AUTOSAR XML (schema 00046)
package /COM/VECTOR/CFG/WORKFLOW/SYSDESC/SYNC
  system SYSTEM: category=ECU_EXTRACT
    system mapping MAPPINGS: data-mappings={sender-receiver-to-signal-group-mapping={data-element=COMPOSITIONTYPE.R_DI_Odo_Pr5_ST3.DI_Odo_Pr5_ST3, signal-group=DI_Odo_Pr5_ST3_e68xmtlkywxgxsdwekdjjhw3t, type-mapping=sender-rec-record-type-mapping=sender-rec-record-element-mapping{application-record-element=Odo_ST3, system-signal=Odo_ST3}}, sender-receiver-to-signal-mapping={data-element=COMPOSITIONTYPE.R_DidA_ExtTest_Pres_ST3.DidA_ExtTest_Pres_ST3, system-signal=DidA_ExtTest_Pres_ST3}, sender-receiver-to-signal-group-mapping={data-element=COMPOSITIONTYPE.R_Ign_Stat_Pr5_ST3.Ign_Stat_Pr5_ST3, signal-group=Ign_Stat_Pr5_ST3_csgs1dv6drms80o1i9p49677w, type-mapping=sender-rec-record-type-mapping=record-element-mappings=[{application-record-element=KG_StartSw_Psd_ST3, system-signal=KG_StartSw_Psd_ST3}, {application-record-element=CRC_Ign_Stat_Pr5_ST3, system-signal=CRC_Ign_Stat_Pr5_ST3}, {application-record-element=Veh_Op_Mode_ST3, system-signal=Veh_Op_Mode_ST3}, {application-record-element=ISw_Stat_ST3, system-signal=ISw_Stat_ST3}, {application-record-element=SQC_Ign_Stat_Pr5_ST3, system-signal=SQC_Ign_Stat_Pr5_ST3}]}, sender-receiver-to-signal-mapping={data-element=COMPOSITIONTYPE.R_PN14_ProdMd_Stat_ST3.PN14_ProdMd_Stat_ST3, system-signal=PN14_ProdMd_Stat_ST3}, sender-receiver-to-signal-mapping={data-element=COMPOSITIONTYPE.R_PN14_SupBat_Volt_ST3.PN14_SupBat_Volt_ST3, system-signal=PN14_SupBat_Volt_ST3}, sender-receiver-to-signal-mapping={data-element=COMPOSITIONTYPE.R_PN14_TransMd_Stat_ST3.PN14_TransMd_Stat_ST3, system-signal=PN14_TransMd_Stat_ST3}, sender-receiver-to-signal-group-mapping={data-element=COMPOSITIONTYPE.R_VSS_TP_Auth_ST3.VSS_TP_Auth_ST3, signal-group=VSS_TP_Auth_ST3_6j4id7sghlvlbroli4wjozjik, type-mapping=sender-rec-array-type-mapping=array-element-mappings=[{indexed-array-element={application-array-element=ARRAY_ELEMENT, index=0}, system-signal=VSS_TP_Auth_0_ST3}, {indexed-array-element={application-array-element=ARRAY_ELEMENT, index=1}, system-signal=VSS_TP_Auth_1_ST3}, {indexed-array-element={application-array-element=ARRAY_ELEMENT, index=2}, system-signal=VSS_TP_Auth_2_ST3}, {indexed-array-element={application-array-element=ARRAY_ELEMENT, index=3}, system-signal=VSS_TP_Auth_3_ST3}, {indexed-array-element={application-array-element=ARRAY_ELEMENT, index=4}, system-signal=VSS_TP_Auth_4_ST3}, {indexed-array-element={application-array-element=ARRAY_ELEMENT, index=5}, system-signal=VSS_TP_Auth_5_ST3}, {indexed-array-element={application-array-element=ARRAY_ELEMENT, index=6}, system-signal=VSS_TP_Auth_6_ST3}, {indexed-array-element={application-array-element=ARRAY_ELEMENT, index=7}, system-signal=VSS_TP_Auth_7_ST3}]}, sender-receiver-to-signal-group-mapping={data-element=COMPOSITIONTYPE.R_VSS_TP_RealTmOffset_ST3.VSS_TP_RealTmOffset_ST3, signal-group=VSS_TP_RealTmOffset_ST3_1t7vc44gftc0wv35k5kgc2in9, type-mapping=sender-rec-array-type-mapping=array-element-mappings=[{indexed-array-element={application-array-element=ARRAY_ELEMENT, index=0}, system-signal=VSS_TP_RealTmOffset_0_ST3}, {indexed-array-element={application-array-element=ARRAY_ELEMENT, index=1}, system-signal=VSS_TP_RealTmOffset_1_ST3}, {indexed-array-element={application-array-element=ARRAY_ELEMENT, index=2}, system-signal=VSS_TP_RealTmOffset_2_ST3}, {indexed-array-element={application-array-element=ARRAY_ELEMENT, index=3}, system-signal=VSS_TP_RealTmOffset_3_ST3}, {indexed-array-element={application-array-element=ARRAY_ELEMENT, index=4}, system-signal=VSS_TP_RealTmOffset_4_ST3}, {indexed-array-element={application-array-element=ARRAY_ELEMENT, index=5}, system-signal=VSS_TP_RealTmOffset_5_ST3}, {indexed-array-element={application-array-element=ARRAY_ELEMENT, index=6}, system-signal=VSS_TP_RealTmOffset_6_ST3}, {indexed-array-element={application-array-element=ARRAY_ELEMENT, index=7}, system-signal=VSS_TP_RealTmOffset_7_ST3}]}, sender-receiver-to-signal-group-mapping={data-element=COMPOSITIONTYPE.R_VSS_TP_SharedSecret_ST3.VSS_TP_SharedSecret_ST3, signal-group=VSS_TP_SharedSecret_ST3_8pj4t8t4rm3tw3pk5hj7vonti, type-mapping=sender-rec-array-type-mapping=array-element-mappings=[{indexed-array-element={application-array-element=ARRAY_ELEMENT, index=0}, system-signal=VSS_TP_SharedSecret_0_ST3}, {indexed-array-element={application-array-element=ARRAY_ELEMENT, index=1}, system-signal=VSS_TP_SharedSecret_1_ST3}, {indexed-array-element={application-array-element=ARRAY_ELEMENT, index=2}, system-signal=VSS_TP_SharedSecret_2_ST3}, {indexed-array-element={application-array-element=ARRAY_ELEMENT, index=3}, system-signal=VSS_TP_SharedSecret_3_ST3}, {indexed-array-element={application-array-element=ARRAY_ELEMENT, index=4}, system-signal=VSS_TP_SharedSecret_4_ST3}, {indexed-array-element={application-array-element=ARRAY_ELEMENT, index=5}, system-signal=VSS_TP_SharedSecret_5_ST3}, {indexed-array-element={application-array-element=ARRAY_ELEMENT, index=6}, system-signal=VSS_TP_SharedSecret_6_ST3}, {indexed-array-element={application-array-element=ARRAY_ELEMENT, index=7}, system-signal=VSS_TP_SharedSecret_7_ST3}]}, sender-receiver-to-signal-group-mapping={data-element=COMPOSITIONTYPE.R_VSS_TP_VIN_ST3.VSS_TP_VIN_ST3, signal-group=VSS_TP_VIN_ST3_bz1xsv84cxzl09j028gn39p69, type-mapping=sender-rec-array-type-mapping=array-element-mappings=[{indexed-array-element={application-array-element=ARRAY_ELEMENT, index=0}, system-signal=VSS_TP_VIN_0_ST3}, {indexed-array-element={application-array-element=ARRAY_ELEMENT, index=1}, system-signal=VSS_TP_VIN_1_ST3}, {indexed-array-element={application-array-element=ARRAY_ELEMENT, index=2}, system-signal=VSS_TP_VIN_2_ST3}, {indexed-array-element={application-array-element=ARRAY_ELEMENT, index=3}, system-signal=VSS_TP_VIN_3_ST3}, {indexed-array-element={application-array-element=ARRAY_ELEMENT, index=4}, system-signal=VSS_TP_VIN_4_ST3}, {indexed-array-element={application-array-element=ARRAY_ELEMENT, index=5}, system-signal=VSS_TP_VIN_5_ST3}, {indexed-array-element={application-array-element=ARRAY_ELEMENT, index=6}, system-signal=VSS_TP_VIN_6_ST3}, {indexed-array-element={application-array-element=ARRAY_ELEMENT, index=7}, system-signal=VSS_TP_VIN_7_ST3}]}, sender-receiver-to-signal-mapping={data-element=COMPOSITIONTYPE.P_Awake_Diag_Actv_ECU4.Awake_Diag_Actv_ECU4, system-signal=Awake_Diag_Actv_ECU4}, sender-receiver-to-signal-mapping={data-element=COMPOSITIONTYPE.P_Awake_Ignition_On_C04.Awake_Ignition_On_C04, system-signal=Awake_Ignition_On_C04}, sender-receiver-to-signal-mapping={data-element=COMPOSITIONTYPE.P_Awake_NwStart_Cluster_ECU4.Awake_NwStart_Cluster_ECU4, system-signal=Awake_NwStart_Cluster_ECU4}, sender-receiver-to-signal-group-mapping={data-element=COMPOSITIONTYPE.P_COM_C04_SGR01_P05.COM_C04_SGR01_P05, signal-group=COM_C04_SGR01_P05_5t2743h81pbparal6h2spw309, type-mapping=sender-rec-record-type-mapping=record-element-mappings=[{application-record-element=COM_C04_Sig004, system-signal=COM_C04_Sig004}, {application-record-element=CRC_COM_C04_SGR01_P05, system-signal=CRC_COM_C04_SGR01_P05}, {application-record-element=SQC_COM_C04_SGR01_P05, system-signal=SQC_COM_C04_SGR01_P05}]}, client-server-to-signal-mapping={call-signal=COM_C04_Sig002_Call, client-server-operation=COMPOSITIONTYPE.P_COM_C04_Sig002.CS_Operation_C04_Sig002, return-signal=COM_C04_Sig002}, sender-receiver-to-signal-mapping={data-element=COMPOSITIONTYPE.P_COM_C04_Sig003.COM_C04_Sig003, system-signal=COM_C04_Sig003}, sender-receiver-to-signal-mapping={data-element=COMPOSITIONTYPE.P_COM_C04_Sig005.COM_C04_Sig005, system-signal=COM_C04_Sig005}, sender-receiver-to-signal-mapping={data-element=COMPOSITIONTYPE.P_COM_C04_Sig006.COM_C04_Sig006, system-signal=COM_C04_Sig006}, sender-receiver-to-signal-mapping={data-element=COMPOSITIONTYPE.P_COM_C04_Sig007.COM_C04_Sig007, system-signal=COM_C04_Sig007}, sender-receiver-to-signal-mapping={data-element=COMPOSITIONTYPE.P_COM_C04_Sig008.COM_C04_Sig008, system-signal=COM_C04_Sig008}, sender-receiver-to-signal-mapping={data-element=COMPOSITIONTYPE.P_COM_C04_Sig01_PN08.COM_C04_Sig01_PN08, system-signal=COM_C04_Sig01_PN08}, sender-receiver-to-signal-mapping={data-element=COMPOSITIONTYPE.P_COM_C04_Sig01_PN17.COM_C04_Sig01_PN17, system-signal=COM_C04_Sig01_PN17}, sender-receiver-to-signal-mapping={data-element=COMPOSITIONTYPE.P_COM_C04_Sig01_PN44.COM_C04_Sig01_PN44, system-signal=COM_C04_Sig01_PN44}, sender-receiver-to-signal-mapping={data-element=COMPOSITIONTYPE.P_COM_C04_Sig01_PN53.COM_C04_Sig01_PN53, system-signal=COM_C04_Sig01_PN53}, sender-receiver-to-signal-mapping={data-element=COMPOSITIONTYPE.P_COM_C04_Sig01_PN62.COM_C04_Sig01_PN62, system-signal=COM_C04_Sig01_PN62}, sender-receiver-to-signal-mapping={data-element=COMPOSITIONTYPE.P_COM_C04_Sig110.COM_C04_Sig110, system-signal=COM_C04_Sig110}, sender-receiver-to-signal-mapping={data-element=COMPOSITIONTYPE.P_COM_C04_Sig111.COM_C04_Sig111, system-signal=COM_C04_Sig111}, sender-receiver-to-signal-mapping={data-element=COMPOSITIONTYPE.P_COM_C04_Sig112.COM_C04_Sig112, system-signal=COM_C04_Sig112}, sender-receiver-to-signal-mapping={data-element=COMPOSITIONTYPE.P_COM_C04_Sig113.COM_C04_Sig113, system-signal=COM_C04_Sig113}, sender-receiver-to-signal-mapping={data-element=COMPOSITIONTYPE.P_COM_C04_Sig114.COM_C04_Sig114, system-signal=COM_C04_Sig114}, sender-receiver-to-signal-mapping={data-element=COMPOSITIONTYPE.P_COM_C04_Sig115.COM_C04_Sig115, system-signal=COM_C04_Sig115}, sender-receiver-to-signal-mapping={data-element=COMPOSITIONTYPE.P_COM_C04_Sig116.COM_C04_Sig116, system-signal=COM_C04_Sig116}, sender-receiver-to-signal-mapping={data-element=COMPOSITIONTYPE.P_COM_C04_Sig117.COM_C04_Sig117, system-signal=COM_C04_Sig117}, sender-receiver-to-signal-mapping={data-element=COMPOSITIONTYPE.P_COM_C04_Sig118.COM_C04_Sig118, system-signal=COM_C04_Sig118}, sender-receiver-to-signal-mapping={data-element=COMPOSITIONTYPE.P_COM_C04_Sig119.COM_C04_Sig119, system-signal=COM_C04_Sig119}, sender-receiver-to-signal-mapping={data-element=COMPOSITIONTYPE.P_COM_C04_Sig120.COM_C04_Sig120, system-signal=COM_C04_Sig120}, sender-receiver-to-signal-mapping={data-element=COMPOSITIONTYPE.P_COM_C04_Sig121.COM_C04_Sig121, system-signal=COM_C04_Sig121}, sender-receiver-to-signal-mapping={data-element=COMPOSITIONTYPE.P_COM_C04_Sig1Cyc_1.COM_C04_Sig1Cyc_1, system-signal=COM_C04_Sig1Cyc_1}, sender-receiver-to-signal-mapping={data-element=COMPOSITIONTYPE.P_COM_C04_Sig221.COM_C04_Sig221, system-signal=COM_C04_Sig221}, sender-receiver-to-signal-mapping={data-element=COMPOSITIONTYPE.P_COM_C04_Sig2Cyc_7.COM_C04_Sig2Cyc_7, system-signal=COM_C04_Sig2Cyc_7}, sender-receiver-to-signal-mapping={data-element=COMPOSITIONTYPE.P_COM_C04_Sig3Cyc_9.COM_C04_Sig3Cyc_9, system-signal=COM_C04_Sig3Cyc_9}, sender-receiver-to-signal-mapping={data-element=COMPOSITIONTYPE.P_COM_C04_Sig4Cyc_24.COM_C04_Sig4Cyc_24, system-signal=COM_C04_Sig4Cyc_24}, sender-receiver-to-signal-mapping={data-element=COMPOSITIONTYPE.P_ECU_ID_C04.ECU_ID_C04, system-signal=ECU_ID_C04}, sender-receiver-to-signal-mapping={data-element=COMPOSITIONTYPE.P_NwId_C04_CAN1.NwId_C04_CAN1, system-signal=NwId_C04_CAN1}, sender-receiver-to-signal-mapping={data-element=COMPOSITIONTYPE.P_NwId_C04_CANFD1.NwId_C04_CANFD1, system-signal=NwId_C04_CANFD1}, sender-receiver-to-signal-mapping={data-element=COMPOSITIONTYPE.P_NwId_C04_ETH_ECU4.NwId_C04_ETH_ECU4, system-signal=NwId_C04_ETH_ECU4}, sender-receiver-to-signal-group-mapping={data-element=COMPOSITIONTYPE.P_ROE.ROE_XX_ST3, signal-group=Diag_RoE_C04_SigGrp01_2ksq5hjijyze6lf3nboiafq6k, type-mapping=sender-rec-record-type-mapping=record-element-mappings=[{application-record-element=ROE_0, system-signal=Diag_RoE_C04_Sig00}, {application-record-element=ROE_4, system-signal=Diag_RoE_C04_Sig04}, {application-record-element=ROE_3, system-signal=Diag_RoE_C04_Sig03}, {application-record-element=ROE_1, system-signal=Diag_RoE_C04_Sig01}, {application-record-element=ROE_2, system-signal=Diag_RoE_C04_Sig02}, {application-record-element=ROE_5, system-signal=Diag_RoE_C04_Sig05}, {application-record-element=ROE_6, system-signal=Diag_RoE_C04_Sig06}, {application-record-element=ROE_7, system-signal=Diag_RoE_C04_Sig07}]}, sender-receiver-to-signal-group-mapping={data-element=COMPOSITIONTYPE.P_VSS_TP_SecTickCount_ST3.VSS_TP_SecTickCount_ST3, signal-group=VSS_TP_SecTickCount_Lvl2_ST3_9eubq13iosat764o0lqh5xb6r, type-mapping=sender-rec-array-type-mapping=array-element-mappings=[{indexed-array-element={application-array-element=ARRAY_ELEMENT, index=0}, system-signal=VSS_TP_SecTickCount_Lvl2_0_ST3}, {indexed-array-element={application-array-element=ARRAY_ELEMENT, index=1}, system-signal=VSS_TP_SecTickCount_Lvl2_1_ST3}, {indexed-array-element={application-array-element=ARRAY_ELEMENT, index=2}, system-signal=VSS_TP_SecTickCount_Lvl2_2_ST3}, {indexed-array-element={application-array-element=ARRAY_ELEMENT, index=3}, system-signal=VSS_TP_SecTickCount_Lvl2_3_ST3}, {indexed-array-element={application-array-element=ARRAY_ELEMENT, index=4}, system-signal=VSS_TP_SecTickCount_Lvl2_4_ST3}, {indexed-array-element={application-array-element=ARRAY_ELEMENT, index=5}, system-signal=VSS_TP_SecTickCount_Lvl2_5_ST3}, {indexed-array-element={application-array-element=ARRAY_ELEMENT, index=6}, system-signal=VSS_TP_SecTickCount_Lvl2_6_ST3}, {indexed-array-element={application-array-element=ARRAY_ELEMENT, index=7}, system-signal=VSS_TP_SecTickCount_Lvl2_7_ST3}]}, sender-receiver-to-signal-mapping={data-element=COMPOSITIONTYPE.P_WakeupRsn_C04_ECU04.WakeupRsn_C04_ECU04, system-signal=WakeupRsn_C04_ECU04}, sender-receiver-to-signal-mapping={data-element=COMPOSITIONTYPE.R_COM_C01_Sig01_PN08.COM_C01_Sig01_PN08, system-signal=COM_C01_Sig01_PN08}, sender-receiver-to-signal-mapping={data-element=COMPOSITIONTYPE.R_COM_C01_Sig01_PN17.COM_C01_Sig01_PN17, system-signal=COM_C01_Sig01_PN17}, sender-receiver-to-signal-mapping={data-element=COMPOSITIONTYPE.R_COM_C01_Sig01_PN44.COM_C01_Sig01_PN44, system-signal=COM_C01_Sig01_PN44}, sender-receiver-to-signal-mapping={data-element=COMPOSITIONTYPE.R_COM_C01_Sig01_PN53.COM_C01_Sig01_PN53, system-signal=COM_C01_Sig01_PN53}, sender-receiver-to-signal-mapping={data-element=COMPOSITIONTYPE.R_COM_C01_Sig01_PN62.COM_C01_Sig01_PN62, system-signal=COM_C01_Sig01_PN62}, sender-receiver-to-signal-mapping={data-element=COMPOSITIONTYPE.R_COM_C07_Sig01_PN08.COM_C07_Sig01_PN08, system-signal=COM_C07_Sig01_PN08}, sender-receiver-to-signal-mapping={data-element=COMPOSITIONTYPE.R_COM_C07_Sig01_PN44.COM_C07_Sig01_PN44, system-signal=COM_C07_Sig01_PN44}, sender-receiver-to-signal-mapping={data-element=COMPOSITIONTYPE.R_COM_C07_Sig01_PN53.COM_C07_Sig01_PN53, system-signal=COM_C07_Sig01_PN53}, sender-receiver-to-signal-mapping={data-element=COMPOSITIONTYPE.R_COM_C0X_Sig111.COM_C0X_Sig111, system-signal=COM_C0X_Sig111}, sender-receiver-to-signal-mapping={data-element=COMPOSITIONTYPE.R_COM_C0X_Sig112.COM_C0X_Sig112, system-signal=COM_C0X_Sig112}, sender-receiver-to-signal-mapping={data-element=COMPOSITIONTYPE.R_COM_C0X_Sig113.COM_C0X_Sig113, system-signal=COM_C0X_Sig113}, sender-receiver-to-signal-mapping={data-element=COMPOSITIONTYPE.R_COM_C0X_Sig114.COM_C0X_Sig114, system-signal=COM_C0X_Sig114}, sender-receiver-to-signal-mapping={data-element=COMPOSITIONTYPE.R_COM_C0X_Sig115.COM_C0X_Sig115, system-signal=COM_C0X_Sig115}, sender-receiver-to-signal-mapping={data-element=COMPOSITIONTYPE.R_COM_C0X_Sig116.COM_C0X_Sig116, system-signal=COM_C0X_Sig116}, sender-receiver-to-signal-mapping={data-element=COMPOSITIONTYPE.R_COM_C0X_Sig117.COM_C0X_Sig117, system-signal=COM_C0X_Sig117}, sender-receiver-to-signal-mapping={data-element=COMPOSITIONTYPE.R_COM_C0X_Sig118.COM_C0X_Sig118, system-signal=COM_C0X_Sig118}, sender-receiver-to-signal-mapping={data-element=COMPOSITIONTYPE.R_COM_C0X_Sig119.COM_C0X_Sig119, system-signal=COM_C0X_Sig119}, sender-receiver-to-signal-mapping={data-element=COMPOSITIONTYPE.R_COM_C0X_Sig120.COM_C0X_Sig120, system-signal=COM_C0X_Sig120}, sender-receiver-to-signal-mapping={data-element=COMPOSITIONTYPE.R_COM_C0X_Sig121.COM_C0X_Sig121, system-signal=COM_C0X_Sig121}, sender-receiver-to-signal-mapping={data-element=COMPOSITIONTYPE.R_COM_C0X_Sig221.COM_C0X_Sig221, system-signal=COM_C0X_Sig221}, sender-receiver-to-signal-mapping={data-element=COMPOSITIONTYPE.R_COM_C10_Sig01_PN08.COM_C10_Sig01_PN08, system-signal=COM_C10_Sig01_PN08}, sender-receiver-to-signal-mapping={data-element=COMPOSITIONTYPE.R_COM_C10_Sig01_PN17.COM_C10_Sig01_PN17, system-signal=COM_C10_Sig01_PN17}, sender-receiver-to-signal-mapping={data-element=COMPOSITIONTYPE.R_COM_C19_Sig002.COM_C19_Sig002, system-signal=COM_C19_Sig002}, sender-receiver-to-signal-mapping={data-element=COMPOSITIONTYPE.R_COM_C19_Sig003.COM_C19_Sig003, system-signal=COM_C19_Sig003}, sender-receiver-to-signal-mapping={data-element=COMPOSITIONTYPE.R_COM_C19_Sig004.COM_C19_Sig004, system-signal=COM_C19_Sig004}, sender-receiver-to-signal-mapping={data-element=COMPOSITIONTYPE.R_COM_C19_Sig005.COM_C19_Sig005, system-signal=COM_C19_Sig005}, sender-receiver-to-signal-mapping={data-element=COMPOSITIONTYPE.R_COM_C19_Sig006.COM_C19_Sig006, system-signal=COM_C19_Sig006}, sender-receiver-to-signal-mapping={data-element=COMPOSITIONTYPE.R_COM_C19_Sig01_PN08.COM_C19_Sig01_PN08, system-signal=COM_C19_Sig01_PN08}, sender-receiver-to-signal-mapping={data-element=COMPOSITIONTYPE.R_COM_C19_Sig01_PN44.COM_C19_Sig01_PN44, system-signal=COM_C19_Sig01_PN44}, sender-receiver-to-signal-mapping={data-element=COMPOSITIONTYPE.R_COM_SL05_Sig001.COM_SL05_Sig001, system-signal=COM_SL05_Sig001}, sender-receiver-to-signal-group-mapping={data-element=COMPOSITIONTYPE.R_PT4_PTCoor4_Pr5_ST3.PT4_PTCoor4_Pr5_ST3, signal-group=PT4_PTCoor4_Pr5_ST3_af4fxb1ykieox3itqdfzs0kpb, type-mapping=sender-rec-record-type-mapping=record-element-mappings=[{application-record-element=PT4_PTCoor_EngStartPN14_Stat_ST3, system-signal=PT4_PTCoor_EngStartPN14_Stat_ST3}, {application-record-element=Rsrv1_PT4_PTCoor_PT_Rdy_Pr5_ST3, system-signal=Rsrv1_PT4_PTCoor_PT_Rdy_Pr5_ST3}, {application-record-element=PT4_PTCoor_PT_Rdy_ST3, system-signal=PT4_PTCoor_PT_Rdy_ST3}, {application-record-element=PT4_PTCoor_SSA_EngSp_ST3, system-signal=PT4_PTCoor_SSA_EngSp_ST3}, {application-record-element=SQC_PT4_PTCoor4_Pr5_ST3, system-signal=SQC_PT4_PTCoor4_Pr5_ST3}, {application-record-element=CRC_PT4_PTCoor4_Pr5_ST3, system-signal=CRC_PT4_PTCoor4_Pr5_ST3}]}, sender-receiver-to-signal-mapping={data-element=COMPOSITIONTYPE.R_RsErr_LIN5_SL05.RsErr_LIN5_SL05, system-signal=RsErr_LIN5_SL05}, sender-receiver-to-signal-group-mapping={data-element=COMPOSITIONTYPE.R_VehSpd8_Pr5_ST3.VehSpd8_Pr5_ST3, signal-group=VehSpd8_Pr5_ST3_168m1ogyookfwuxfakr38tbmv, type-mapping=sender-rec-record-type-mapping=record-element-mappings=[{application-record-element=VehSpd8_ST3, system-signal=VehSpd8_ST3}, {application-record-element=SQC_VehSpd8_Pr5_ST3, system-signal=SQC_VehSpd8_Pr5_ST3}, {application-record-element=CRC_VehSpd8_Pr5_ST3, system-signal=CRC_VehSpd8_Pr5_ST3}]}, sender-receiver-to-signal-group-mapping={data-element=COMPOSITIONTYPE.R_VSS_TP_SecTickCount_ST3.VSS_TP_SecTickCount_ST3, signal-group=VSS_TP_SecTickCount_Lvl1_ST3_mzmfdqtqz5kvv1kfpvg0kql3, type-mapping=sender-rec-array-type-mapping=array-element-mappings=[{indexed-array-element={application-array-element=ARRAY_ELEMENT, index=0}, system-signal=VSS_TP_SecTickCount_Lvl1_0_ST3}, {indexed-array-element={application-array-element=ARRAY_ELEMENT, index=1}, system-signal=VSS_TP_SecTickCount_Lvl1_1_ST3}, {indexed-array-element={application-array-element=ARRAY_ELEMENT, index=2}, system-signal=VSS_TP_SecTickCount_Lvl1_2_ST3}, {indexed-array-element={application-array-element=ARRAY_ELEMENT, index=3}, system-signal=VSS_TP_SecTickCount_Lvl1_3_ST3}, {indexed-array-element={application-array-element=ARRAY_ELEMENT, index=4}, system-signal=VSS_TP_SecTickCount_Lvl1_4_ST3}, {indexed-array-element={application-array-element=ARRAY_ELEMENT, index=5}, system-signal=VSS_TP_SecTickCount_Lvl1_5_ST3}, {indexed-array-element={application-array-element=ARRAY_ELEMENT, index=6}, system-signal=VSS_TP_SecTickCount_Lvl1_6_ST3}, {indexed-array-element={application-array-element=ARRAY_ELEMENT, index=7}, system-signal=VSS_TP_SecTickCount_Lvl1_7_ST3}]}, sender-receiver-to-signal-mapping={data-element=COMPOSITIONTYPE.R_Actv_Line_Stat_ST3.Actv_Line_Stat_ST3, system-signal=Actv_Line_Stat_ST3}, sender-receiver-to-signal-mapping={data-element=COMPOSITIONTYPE.R_COM_C0X_Sig110.COM_C0X_Sig110, system-signal=COM_C0X_Sig110}, sender-receiver-to-signal-mapping={data-element=COMPOSITIONTYPE.R_WakeupStat_Cluster4_LIN_S5.WakeupStat_Cluster4_LIN_S5, system-signal=WakeupStat_Cluster4_LIN_S5}}
      sw-mappings:
        swc to ecu mapping XDIS_f1961gnsrozhfnl3v5xsvpqsz: ecu-instance=ECU4_CRN  # UB:Derived from original system description
    root-software-compositions:
      root sw composition prototype COMPOSITIONTYPE: flat-map=FLATMAP, software-composition=COMPOSITIONTYPE
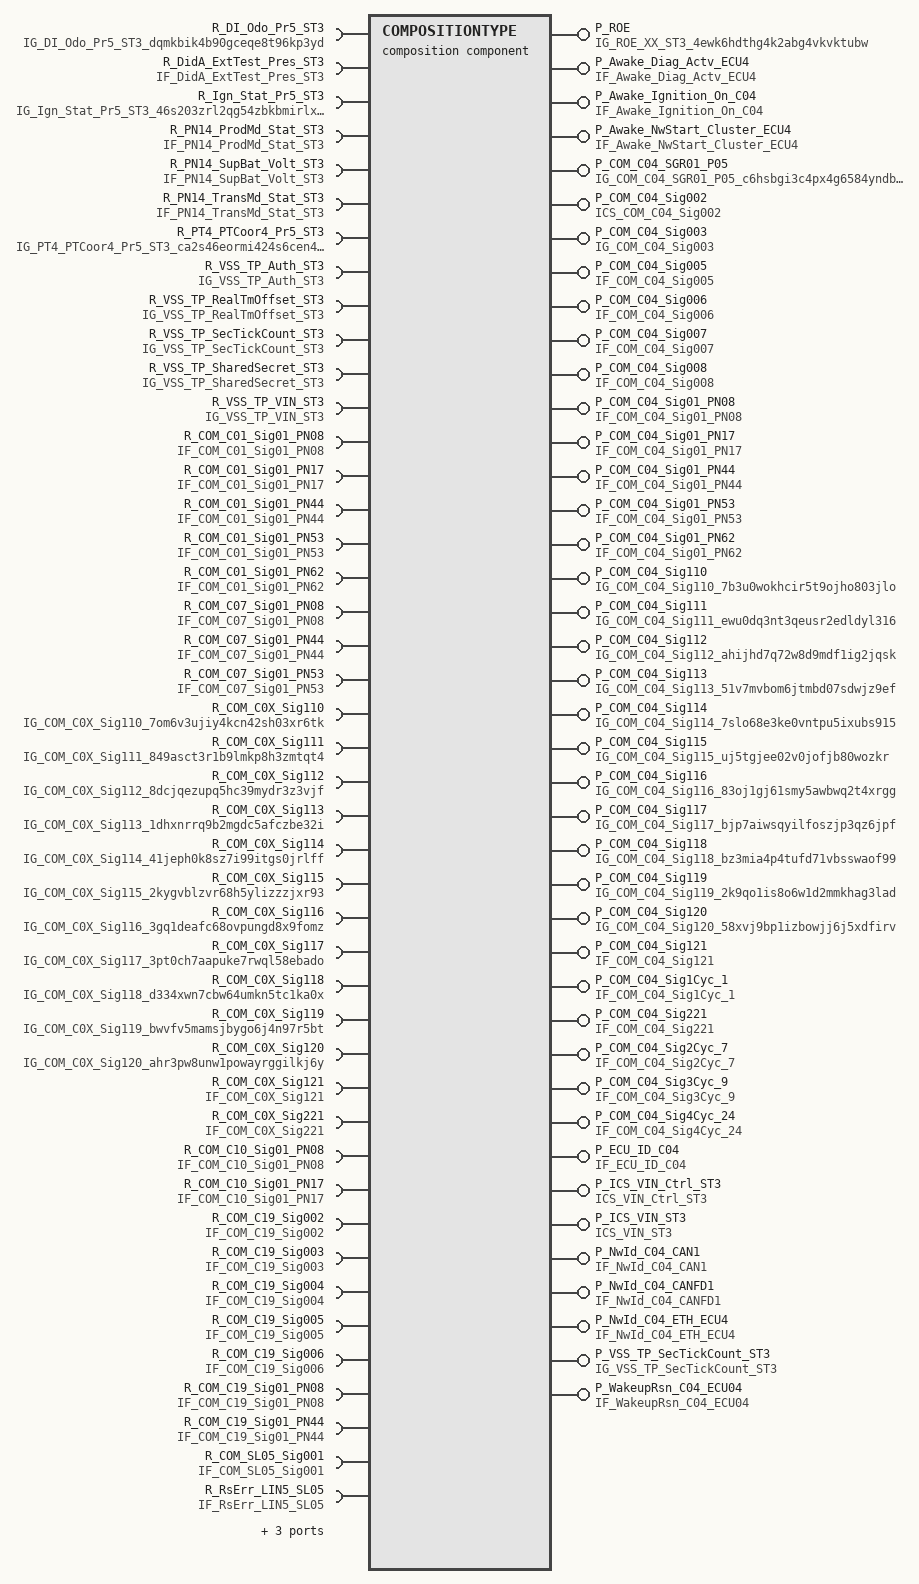
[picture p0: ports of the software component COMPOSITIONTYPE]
  composition sw component type COMPOSITIONTYPE  # ECU COMP ECU4 CRN | UB:Derived from original system description
    provide port P_ROE: nonqueued-sender-com-spec{data-element=ROE_XX_ST3, init-value=constant-reference=XDIS_epntk9hnintc34egvtksqi4oo}, provided-interface=IG_ROE_XX_ST3_4ewk6hdthg4k2abg4vkvktubw  # Response on Event (degraded)
    12 x require port:
      R_DI_Odo_Pr5_ST3: nonqueued-receiver-com-spec{data-element=DI_Odo_Pr5_ST3, end-to-end-transformation-com-spec-props=disable-end-to-end-check=true, init-value=constant-reference=XDIS_6b75pabydagdo3iwsn1mn0uh1}, required-interface=IG_DI_Odo_Pr5_ST3_dqmkbik4b90gceqe8t96kp3yd  # DriverInformation Odometer (degraded)
      R_DidA_ExtTest_Pres_ST3: nonqueued-receiver-com-spec{data-element=DidA_ExtTest_Pres_ST3, init-value=constant-reference=XDIS_ays1a6ktv25pr5ggjl5ntdf5h}, required-interface=IF_DidA_ExtTest_Pres_ST3  # DidA external tester present
      R_Ign_Stat_Pr5_ST3: nonqueued-receiver-com-spec{data-element=Ign_Stat_Pr5_ST3, end-to-end-transformation-com-spec-props{disable-end-to-end-check=false, max-delta-counter=3, max-error-state-init=0, max-error-state-invalid=0, max-error-state-valid=0, min-ok-state-init=1, min-ok-state-invalid=1, min-ok-state-valid=1, window-size=10}, init-value=constant-reference=XDIS_9fnatjo7ibmc7ug14uhxholnb}, required-interface=IG_Ign_Stat_Pr5_ST3_46s203zrl2qg54zbkbmirlx2b  # Ignition state (degraded)
      R_PN14_ProdMd_Stat_ST3: nonqueued-receiver-com-spec{data-element=PN14_ProdMd_Stat_ST3, init-value=constant-reference=XDIS_1sbl03n5g1wzhawz3y1aoi9p4}, required-interface=IF_PN14_ProdMd_Stat_ST3  # Powernet production mode state
      R_PN14_SupBat_Volt_ST3: nonqueued-receiver-com-spec{data-element=PN14_SupBat_Volt_ST3, init-value=constant-reference=XDIS_1d3ai2d8h1n3nb7ayhambew4d}, required-interface=IF_PN14_SupBat_Volt_ST3  # Supply battery voltage
      R_PN14_TransMd_Stat_ST3: nonqueued-receiver-com-spec{data-element=PN14_TransMd_Stat_ST3, init-value=constant-reference=XDIS_csegq0grcmpyfro5u6kyzxmql}, required-interface=IF_PN14_TransMd_Stat_ST3  # Powernet transport mode status
      R_PT4_PTCoor4_Pr5_ST3: nonqueued-receiver-com-spec{data-element=PT4_PTCoor4_Pr5_ST3, end-to-end-transformation-com-spec-props{disable-end-to-end-check=false, max-delta-counter=3, max-error-state-init=0, max-error-state-invalid=0, max-error-state-valid=0, min-ok-state-init=1, min-ok-state-invalid=1, min-ok-state-valid=1, window-size=10}, init-value=constant-reference=XDIS_clk6954ou39yiqqejf1k65voj}, required-interface=IG_PT4_PTCoor4_Pr5_ST3_ca2s46eormi424s6cen48bry3  # PT4_PTCoor4_Pr5_ST3 (degraded)
      R_VSS_TP_Auth_ST3: nonqueued-receiver-com-spec{data-element=VSS_TP_Auth_ST3, init-value=constant-reference=XDIS_12zcafvpuxi1hcqhklsbnv4pg}, required-interface=IG_VSS_TP_Auth_ST3  # Vehicle Security System Transport Protocol for authentication broadcast
      R_VSS_TP_RealTmOffset_ST3: nonqueued-receiver-com-spec{data-element=VSS_TP_RealTmOffset_ST3, init-value=constant-reference=XDIS_12zcafvpuxi1hcqhklsbnv4pg}, required-interface=IG_VSS_TP_RealTmOffset_ST3  # Vehicle Security System Transport Protocol for real time offset broadcast
      R_VSS_TP_SecTickCount_ST3: nonqueued-receiver-com-spec{data-element=VSS_TP_SecTickCount_ST3, init-value=constant-reference=XDIS_12zcafvpuxi1hcqhklsbnv4pg}, required-interface=IG_VSS_TP_SecTickCount_ST3  # Vehicle Security System Transport Protocol for secure tick count
      R_VSS_TP_SharedSecret_ST3: nonqueued-receiver-com-spec{data-element=VSS_TP_SharedSecret_ST3, init-value=constant-reference=XDIS_12zcafvpuxi1hcqhklsbnv4pg}, required-interface=IG_VSS_TP_SharedSecret_ST3  # Vehicle Security System Transport Protocol for shared secret broadcast
      R_VSS_TP_VIN_ST3: nonqueued-receiver-com-spec{data-element=VSS_TP_VIN_ST3, init-value=constant-reference=XDIS_3jcrrl3ll1e4yr6lszlogfin7}, required-interface=IG_VSS_TP_VIN_ST3  # Vehicle Security System Transport Protocol for Vehicle Identification Number
    40 x provide port:
      P_Awake_Diag_Actv_ECU4: nonqueued-sender-com-spec{data-element=Awake_Diag_Actv_ECU4, init-value=constant-reference=XDIS_69jg6h6dhtx5icztjq3x4sq6f}, provided-interface=IF_Awake_Diag_Actv_ECU4  # Awake_Diag_Actv_ECU4
      P_Awake_Ignition_On_C04: nonqueued-sender-com-spec{data-element=Awake_Ignition_On_C04, init-value=constant-reference=XDIS_69jg6h6dhtx5icztjq3x4sq6f}, provided-interface=IF_Awake_Ignition_On_C04  # Awake_Ignition_On_C04
      P_Awake_NwStart_Cluster_ECU4: nonqueued-sender-com-spec{data-element=Awake_NwStart_Cluster_ECU4, init-value=constant-reference=XDIS_h5tcyk98kzbgrc5svasomeyt}, provided-interface=IF_Awake_NwStart_Cluster_ECU4  # Awake_NwStart_Cluster_ECU4
      P_COM_C04_SGR01_P05: nonqueued-sender-com-spec{data-element=COM_C04_SGR01_P05, init-value=constant-reference=XDIS_d8ygj72mhg3r09d8kaikrluou}, provided-interface=IG_COM_C04_SGR01_P05_c6hsbgi3c4px4g6584yndbcpa  # COM_C04_SGR01_P05 (degraded)
      P_COM_C04_Sig002: server-com-spec{operation=CS_Operation_C04_Sig002, queue-length=1}, provided-interface=ICS_COM_C04_Sig002  # ICS COM C04 Sig 002
      P_COM_C04_Sig003: nonqueued-sender-com-spec{data-element=COM_C04_Sig003, init-value=constant-reference=XDIS_76qrtrdtukkzs2abeyipv4tw8}, provided-interface=IG_COM_C04_Sig003  # IG COM C04 Sig 003
      P_COM_C04_Sig005: nonqueued-sender-com-spec{data-element=COM_C04_Sig005, init-value=constant-reference=XDIS_m223zh8cvs0ihyqs8dhx6193}, provided-interface=IF_COM_C04_Sig005  # COM C04 Sig 005
      P_COM_C04_Sig006: nonqueued-sender-com-spec{data-element=COM_C04_Sig006, init-value=constant-reference=XDIS_6xfhgyu1ikjrqljmxhsy1gdbn}, provided-interface=IF_COM_C04_Sig006  # COM C04 Sig 006
      P_COM_C04_Sig007: nonqueued-sender-com-spec{data-element=COM_C04_Sig007, init-value=constant-reference=XDIS_c5zwxf9u0v1jevpkuyek992t0}, provided-interface=IF_COM_C04_Sig007  # COM C04 Sig 007
      P_COM_C04_Sig008: nonqueued-sender-com-spec{data-element=COM_C04_Sig008, init-value=constant-reference=XDIS_3x52498l7coo3oyyni2d5c5j2}, provided-interface=IF_COM_C04_Sig008  # replicated from COM C04 Sig 008
      P_COM_C04_Sig01_PN08: nonqueued-sender-com-spec{data-element=COM_C04_Sig01_PN08, init-value=constant-reference=XDIS_927sr7e5jercp2xdgv74pbpok}, provided-interface=IF_COM_C04_Sig01_PN08  # COM_C04_Sig01_PN08
      P_COM_C04_Sig01_PN17: nonqueued-sender-com-spec{data-element=COM_C04_Sig01_PN17, init-value=constant-reference=XDIS_927sr7e5jercp2xdgv74pbpok}, provided-interface=IF_COM_C04_Sig01_PN17  # COM_C04_Sig01_PN17
      P_COM_C04_Sig01_PN44: nonqueued-sender-com-spec{data-element=COM_C04_Sig01_PN44, init-value=constant-reference=XDIS_927sr7e5jercp2xdgv74pbpok}, provided-interface=IF_COM_C04_Sig01_PN44  # COM_C04_Sig01_PN44
      P_COM_C04_Sig01_PN53: nonqueued-sender-com-spec{data-element=COM_C04_Sig01_PN53, init-value=constant-reference=XDIS_927sr7e5jercp2xdgv74pbpok}, provided-interface=IF_COM_C04_Sig01_PN53  # COM_C04_Sig01_PN53
      P_COM_C04_Sig01_PN62: nonqueued-sender-com-spec{data-element=COM_C04_Sig01_PN62, init-value=constant-reference=XDIS_927sr7e5jercp2xdgv74pbpok}, provided-interface=IF_COM_C04_Sig01_PN62  # COM_C04_Sig01_PN62
      P_COM_C04_Sig110: nonqueued-sender-com-spec{data-element=COM_C04_Sig110, init-value=constant-reference=XDIS_c3mj3wt15yz2lvo6vab7ajqft}, provided-interface=IG_COM_C04_Sig110_7b3u0wokhcir5t9ojho803jlo  # IG COM C04 Sig 110 (degraded)
      P_COM_C04_Sig111: nonqueued-sender-com-spec{data-element=COM_C04_Sig111, init-value=constant-reference=XDIS_7szikvdwzq1b962h5gxvmrg2u}, provided-interface=IG_COM_C04_Sig111_ewu0dq3nt3qeusr2edldyl316  # IG COM C04 Sig 111 (degraded)
      P_COM_C04_Sig112: nonqueued-sender-com-spec{data-element=COM_C04_Sig112, init-value=constant-reference=XDIS_6tzpenvfivlvlq0j4xgjdh9k7}, provided-interface=IG_COM_C04_Sig112_ahijhd7q72w8d9mdf1ig2jqsk  # IG COM C04 Sig 112 (degraded)
      P_COM_C04_Sig113: nonqueued-sender-com-spec{data-element=COM_C04_Sig113, init-value=constant-reference=XDIS_yt0ngo0kc6dn4f2zwu57kafr}, provided-interface=IG_COM_C04_Sig113_51v7mvbom6jtmbd07sdwjz9ef  # IG COM C04 Sig 113 (degraded)
      P_COM_C04_Sig114: nonqueued-sender-com-spec{data-element=COM_C04_Sig114, init-value=constant-reference=XDIS_df34ublxsfrlyl4twdm6pzpqv}, provided-interface=IG_COM_C04_Sig114_7slo68e3ke0vntpu5ixubs915  # IG COM C04 Sig 114 (degraded)
      P_COM_C04_Sig115: nonqueued-sender-com-spec{data-element=COM_C04_Sig115, init-value=constant-reference=XDIS_ce5s2juhaacvffo732sn2kms7}, provided-interface=IG_COM_C04_Sig115_uj5tgjee02v0jofjb80wozkr  # IG COM C04 Sig 115 (degraded)
      P_COM_C04_Sig116: nonqueued-sender-com-spec{data-element=COM_C04_Sig116, init-value=constant-reference=XDIS_6jf2057vzskie1sao2lzuvwe6}, provided-interface=IG_COM_C04_Sig116_83oj1gj61smy5awbwq2t4xrgg  # IG COM C04 Sig 116 (degraded)
      P_COM_C04_Sig117: nonqueued-sender-com-spec{data-element=COM_C04_Sig117, init-value=constant-reference=XDIS_37u1vz1oxwgimiivpur7gcsbr}, provided-interface=IG_COM_C04_Sig117_bjp7aiwsqyilfoszjp3qz6jpf  # IG COM C04 Sig 117 (degraded)
      P_COM_C04_Sig118: nonqueued-sender-com-spec{data-element=COM_C04_Sig118, init-value=constant-reference=XDIS_7m32ze473bspgglxjgcvf4996}, provided-interface=IG_COM_C04_Sig118_bz3mia4p4tufd71vbsswaof99  # IG COM C04 Sig 118 (degraded)
      P_COM_C04_Sig119: nonqueued-sender-com-spec{data-element=COM_C04_Sig119, init-value=constant-reference=XDIS_1ro73n58nna7ivlclcwrm9xvh}, provided-interface=IG_COM_C04_Sig119_2k9qo1is8o6w1d2mmkhag3lad  # IG COM C04 Sig 119 (degraded)
      P_COM_C04_Sig120: nonqueued-sender-com-spec{data-element=COM_C04_Sig120, init-value=constant-reference=XDIS_1czwqwie4vy3rtud2d7rlsckr}, provided-interface=IG_COM_C04_Sig120_58xvj9bp1izbowjj6j5xdfirv  # IG COM C04 Sig 120 (degraded)
      P_COM_C04_Sig121: nonqueued-sender-com-spec{data-element=COM_C04_Sig121, init-value=constant-reference=XDIS_8lojm7nsrlij3camx6n94jzo8}, provided-interface=IF_COM_C04_Sig121  # IF COM C04 Sig 121
      P_COM_C04_Sig1Cyc_1: nonqueued-sender-com-spec{data-element=COM_C04_Sig1Cyc_1, init-value=constant-reference=XDIS_82ba1o608pvmae4mjoh2xupug}, provided-interface=IF_COM_C04_Sig1Cyc_1  # 1 Bit cyclic Signal
      P_COM_C04_Sig221: nonqueued-sender-com-spec{data-element=COM_C04_Sig221, init-value=constant-reference=XDIS_1iem5v7ndkwhbdnvd3iw0c32a}, provided-interface=IF_COM_C04_Sig221  # COM C04 Sig 121
      P_COM_C04_Sig2Cyc_7: nonqueued-sender-com-spec{data-element=COM_C04_Sig2Cyc_7, init-value=constant-reference=XDIS_9br2cbqn3yqyive818t7irvmp}, provided-interface=IF_COM_C04_Sig2Cyc_7  # 7 Bit Cyclic Signal
      P_COM_C04_Sig3Cyc_9: nonqueued-sender-com-spec{data-element=COM_C04_Sig3Cyc_9, init-value=constant-reference=XDIS_4511s3aabcgdkpe2axjc7gzxv}, provided-interface=IF_COM_C04_Sig3Cyc_9  # 9 Bit Cyclic Signal
      P_COM_C04_Sig4Cyc_24: nonqueued-sender-com-spec{data-element=COM_C04_Sig4Cyc_24, init-value=constant-reference=XDIS_eaw5br234rla8x8gro0ue6n0p}, provided-interface=IF_COM_C04_Sig4Cyc_24  # 24 bit cyclic signal
      P_ECU_ID_C04: nonqueued-sender-com-spec{data-element=ECU_ID_C04, init-value=constant-reference=XDIS_2ifmi9jurj9hq7gf07q950soq}, provided-interface=IF_ECU_ID_C04  # ECU_ID_C04
      P_ICS_VIN_Ctrl_ST3: provided-interface=ICS_VIN_Ctrl_ST3  # Vehicle Identification Number control
      P_ICS_VIN_ST3: provided-interface=ICS_VIN_ST3  # Vehicle Identification Number
      P_NwId_C04_CAN1: nonqueued-sender-com-spec{data-element=NwId_C04_CAN1, init-value=constant-reference=XDIS_86cgixlat1gzw7ridya4l3yvg}, provided-interface=IF_NwId_C04_CAN1  # NwId_C04_CAN1
      P_NwId_C04_CANFD1: nonqueued-sender-com-spec{data-element=NwId_C04_CANFD1, init-value=constant-reference=XDIS_ewn2l7a4y8reumsogphyjzww5}, provided-interface=IF_NwId_C04_CANFD1  # NwId_C04_CANFD1
      P_NwId_C04_ETH_ECU4: nonqueued-sender-com-spec{data-element=NwId_C04_ETH_ECU4, init-value=constant-reference=XDIS_ey3cre7b3cnomwxl2ccjj953u}, provided-interface=IF_NwId_C04_ETH_ECU4  # Nw Id C04 ETH ECU4
      P_VSS_TP_SecTickCount_ST3: nonqueued-sender-com-spec{data-element=VSS_TP_SecTickCount_ST3, init-value=constant-reference=XDIS_12zcafvpuxi1hcqhklsbnv4pg}, provided-interface=IG_VSS_TP_SecTickCount_ST3  # Vehicle Security System Transport Protocol for secure tick count
      P_WakeupRsn_C04_ECU04: nonqueued-sender-com-spec{data-element=WakeupRsn_C04_ECU04, init-value=constant-reference=XDIS_8ymqkhaj6x9epi3t7udp3cvlw}, provided-interface=IF_WakeupRsn_C04_ECU04  # WakeupRsn_C04_ECU04
    35 x require port:
      R_COM_C01_Sig01_PN08: nonqueued-receiver-com-spec{data-element=COM_C01_Sig01_PN08, init-value=constant-reference=XDIS_927sr7e5jercp2xdgv74pbpok}, required-interface=IF_COM_C01_Sig01_PN08  # COM_C01_Sig01_PN08
      R_COM_C01_Sig01_PN17: nonqueued-receiver-com-spec{data-element=COM_C01_Sig01_PN17, init-value=constant-reference=XDIS_927sr7e5jercp2xdgv74pbpok}, required-interface=IF_COM_C01_Sig01_PN17  # COM_C01_Sig01_PN17
      R_COM_C01_Sig01_PN44: nonqueued-receiver-com-spec{data-element=COM_C01_Sig01_PN44, init-value=constant-reference=XDIS_927sr7e5jercp2xdgv74pbpok}, required-interface=IF_COM_C01_Sig01_PN44  # COM_C01_Sig01_PN44
      R_COM_C01_Sig01_PN53: nonqueued-receiver-com-spec{data-element=COM_C01_Sig01_PN53, init-value=constant-reference=XDIS_927sr7e5jercp2xdgv74pbpok}, required-interface=IF_COM_C01_Sig01_PN53  # COM_C01_Sig01_PN53
      R_COM_C01_Sig01_PN62: nonqueued-receiver-com-spec{data-element=COM_C01_Sig01_PN62, init-value=constant-reference=XDIS_927sr7e5jercp2xdgv74pbpok}, required-interface=IF_COM_C01_Sig01_PN62  # COM_C01_Sig01_PN62
      R_COM_C07_Sig01_PN08: nonqueued-receiver-com-spec{data-element=COM_C07_Sig01_PN08, init-value=constant-reference=XDIS_927sr7e5jercp2xdgv74pbpok}, required-interface=IF_COM_C07_Sig01_PN08  # COM_C07_Sig01_PN08
      R_COM_C07_Sig01_PN44: nonqueued-receiver-com-spec{data-element=COM_C07_Sig01_PN44, init-value=constant-reference=XDIS_927sr7e5jercp2xdgv74pbpok}, required-interface=IF_COM_C07_Sig01_PN44  # COM_C07_Sig01_PN44
      R_COM_C07_Sig01_PN53: nonqueued-receiver-com-spec{data-element=COM_C07_Sig01_PN53, init-value=constant-reference=XDIS_927sr7e5jercp2xdgv74pbpok}, required-interface=IF_COM_C07_Sig01_PN53  # COM_C07_Sig01_PN53
      R_COM_C0X_Sig110: nonqueued-receiver-com-spec{data-element=COM_C0X_Sig110, init-value=constant-reference=XDIS_b7prl6oobd5u5033mtut4jwvn}, required-interface=IG_COM_C0X_Sig110_7om6v3ujiy4kcn42sh03xr6tk  # IG COM C0X Sig 110 (degraded)
      R_COM_C0X_Sig111: nonqueued-receiver-com-spec{data-element=COM_C0X_Sig111, init-value=constant-reference=XDIS_7szikvdwzq1b962h5gxvmrg2u}, required-interface=IG_COM_C0X_Sig111_849asct3r1b9lmkp8h3zmtqt4  # IG COM C0X Sig 111 (degraded)
      R_COM_C0X_Sig112: nonqueued-receiver-com-spec{data-element=COM_C0X_Sig112, init-value=constant-reference=XDIS_6tzpenvfivlvlq0j4xgjdh9k7}, required-interface=IG_COM_C0X_Sig112_8dcjqezupq5hc39mydr3z3vjf  # IG COM C0X Sig 112 (degraded)
      R_COM_C0X_Sig113: nonqueued-receiver-com-spec{data-element=COM_C0X_Sig113, init-value=constant-reference=XDIS_yt0ngo0kc6dn4f2zwu57kafr}, required-interface=IG_COM_C0X_Sig113_1dhxnrrq9b2mgdc5afczbe32i  # IG COM C0X Sig 113 (degraded)
      R_COM_C0X_Sig114: nonqueued-receiver-com-spec{data-element=COM_C0X_Sig114, init-value=constant-reference=XDIS_df34ublxsfrlyl4twdm6pzpqv}, required-interface=IG_COM_C0X_Sig114_41jeph0k8sz7i99itgs0jrlff  # IG COM C0X Sig 114 (degraded)
      R_COM_C0X_Sig115: nonqueued-receiver-com-spec{data-element=COM_C0X_Sig115, init-value=constant-reference=XDIS_ce5s2juhaacvffo732sn2kms7}, required-interface=IG_COM_C0X_Sig115_2kygvblzvr68h5ylizzzjxr93  # IG COM C0X Sig 115 (degraded)
      R_COM_C0X_Sig116: nonqueued-receiver-com-spec{data-element=COM_C0X_Sig116, init-value=constant-reference=XDIS_6jf2057vzskie1sao2lzuvwe6}, required-interface=IG_COM_C0X_Sig116_3gq1deafc68ovpungd8x9fomz  # IG COM C0X Sig 116 (degraded)
      R_COM_C0X_Sig117: nonqueued-receiver-com-spec{data-element=COM_C0X_Sig117, init-value=constant-reference=XDIS_37u1vz1oxwgimiivpur7gcsbr}, required-interface=IG_COM_C0X_Sig117_3pt0ch7aapuke7rwql58ebado  # IG COM C0X Sig 117 (degraded)
      R_COM_C0X_Sig118: nonqueued-receiver-com-spec{data-element=COM_C0X_Sig118, init-value=constant-reference=XDIS_7m32ze473bspgglxjgcvf4996}, required-interface=IG_COM_C0X_Sig118_d334xwn7cbw64umkn5tc1ka0x  # IG COM C0X Sig 118 (degraded)
      R_COM_C0X_Sig119: nonqueued-receiver-com-spec{data-element=COM_C0X_Sig119, init-value=constant-reference=XDIS_1ro73n58nna7ivlclcwrm9xvh}, required-interface=IG_COM_C0X_Sig119_bwvfv5mamsjbygo6j4n97r5bt  # IG COM C0X Sig 119 (degraded)
      R_COM_C0X_Sig120: nonqueued-receiver-com-spec{data-element=COM_C0X_Sig120, init-value=constant-reference=XDIS_1czwqwie4vy3rtud2d7rlsckr}, required-interface=IG_COM_C0X_Sig120_ahr3pw8unw1powayrggilkj6y  # IG COM C0X Sig 120 (degraded)
      R_COM_C0X_Sig121: nonqueued-receiver-com-spec{data-element=COM_C0X_Sig121, init-value=constant-reference=XDIS_8lojm7nsrlij3camx6n94jzo8}, required-interface=IF_COM_C0X_Sig121  # IF COM C0X Sig 121
      R_COM_C0X_Sig221: nonqueued-receiver-com-spec{data-element=COM_C0X_Sig221, init-value=constant-reference=XDIS_1iem5v7ndkwhbdnvd3iw0c32a}, required-interface=IF_COM_C0X_Sig221  # COM C0X Sig 121
      R_COM_C10_Sig01_PN08: nonqueued-receiver-com-spec{data-element=COM_C10_Sig01_PN08, init-value=constant-reference=XDIS_927sr7e5jercp2xdgv74pbpok}, required-interface=IF_COM_C10_Sig01_PN08  # COM_C10_Sig01_PN08
      R_COM_C10_Sig01_PN17: nonqueued-receiver-com-spec{data-element=COM_C10_Sig01_PN17, init-value=constant-reference=XDIS_927sr7e5jercp2xdgv74pbpok}, required-interface=IF_COM_C10_Sig01_PN17  # COM_C10_Sig01_PN17
      R_COM_C19_Sig002: nonqueued-receiver-com-spec{data-element=COM_C19_Sig002, init-value=constant-reference=XDIS_3x52498l7coo3oyyni2d5c5j2}, required-interface=IF_COM_C19_Sig002  # COM_C19_Sig002
      R_COM_C19_Sig003: nonqueued-receiver-com-spec{data-element=COM_C19_Sig003, init-value=constant-reference=XDIS_cynynxvcrwcjj9mh2pni0aw3f}, required-interface=IF_COM_C19_Sig003  # COM_C19_Sig003
      R_COM_C19_Sig004: nonqueued-receiver-com-spec{data-element=COM_C19_Sig004, init-value=constant-reference=XDIS_3x52498l7coo3oyyni2d5c5j2}, required-interface=IF_COM_C19_Sig004  # COM_C19_Sig004
      R_COM_C19_Sig005: nonqueued-receiver-com-spec{data-element=COM_C19_Sig005, init-value=constant-reference=XDIS_c5zwxf9u0v1jevpkuyek992t0}, required-interface=IF_COM_C19_Sig005  # COM_C19_Sig005
      R_COM_C19_Sig006: nonqueued-receiver-com-spec{data-element=COM_C19_Sig006, init-value=constant-reference=XDIS_6xfhgyu1ikjrqljmxhsy1gdbn}, required-interface=IF_COM_C19_Sig006  # COM_C19_Sig006
      R_COM_C19_Sig01_PN08: nonqueued-receiver-com-spec{data-element=COM_C19_Sig01_PN08, init-value=constant-reference=XDIS_927sr7e5jercp2xdgv74pbpok}, required-interface=IF_COM_C19_Sig01_PN08  # COM_C19_Sig01_PN08
      R_COM_C19_Sig01_PN44: nonqueued-receiver-com-spec{data-element=COM_C19_Sig01_PN44, init-value=constant-reference=XDIS_927sr7e5jercp2xdgv74pbpok}, required-interface=IF_COM_C19_Sig01_PN44  # COM_C19_Sig01_PN44
      R_COM_SL05_Sig001: nonqueued-receiver-com-spec{data-element=COM_SL05_Sig001, init-value=constant-reference=XDIS_ckr3lp5wr0cqe6i2oclzuasuk}, required-interface=IF_COM_SL05_Sig001  # -
      R_RsErr_LIN5_SL05: nonqueued-receiver-com-spec{data-element=RsErr_LIN5_SL05, init-value=constant-reference=XDIS_h5tcyk98kzbgrc5svasomeyt}, required-interface=IF_RsErr_LIN5_SL05  # RsErr_LIN5_SL05
      R_VehSpd8_Pr5_ST3: nonqueued-receiver-com-spec{data-element=VehSpd8_Pr5_ST3, end-to-end-transformation-com-spec-props{disable-end-to-end-check=false, max-delta-counter=3, max-error-state-init=0, max-error-state-invalid=0, max-error-state-valid=0, min-ok-state-init=1, min-ok-state-invalid=1, min-ok-state-valid=1, window-size=10}, init-value=constant-reference=XDIS_dj45cy8ua216iwtra2tj416zq}, required-interface=IG_VehSpd8_Pr5_ST3_atci5a3rslji054k0igvxyzqz  # vehicle Spd 8 ST3 (degraded)
      R_Actv_Line_Stat_ST3: nonqueued-receiver-com-spec{data-element=Actv_Line_Stat_ST3, init-value=constant-reference=XDIS_70kx5sniz2mav2x11hrmvjbpo}, required-interface=IF_Actv_Line_Stat_ST3  # Activation Line state
      R_WakeupStat_Cluster4_LIN_S5: nonqueued-receiver-com-spec{data-element=WakeupStat_Cluster4_LIN_S5, init-value=constant-reference=XDIS_39591keljtic2b4b13zudoeg0}, required-interface=IF_WakeupStat_Cluster4_LIN_S5  # Wakeup reason - LIN Slave 5 Cluster 4
    component Det: type=Det
    component Csm: type=Csm
  end to end protection set E2EPROTECTIONSET
  port interface mapping set PORTINTERFACEMAPPINGSET
